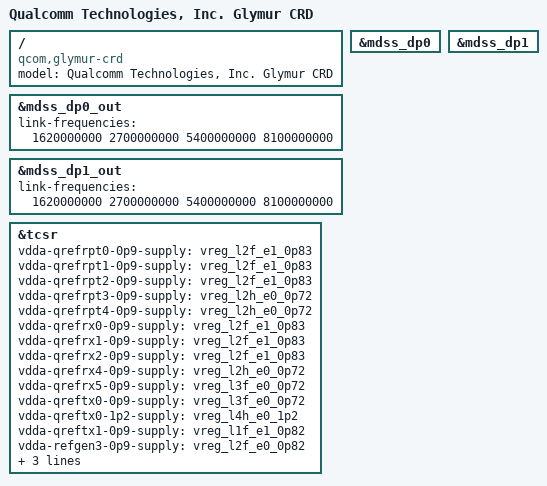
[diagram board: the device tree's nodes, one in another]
// SPDX-License-Identifier: BSD-3-Clause
/*
 * Copyright (c) Qualcomm Technologies, Inc. and/or its subsidiaries.
 */

/dts-v1/;

#include "glymur.dtsi"
#include "glymur-crd.dtsi"

/ {
	model = "Qualcomm Technologies, Inc. Glymur CRD";
	compatible = "qcom,glymur-crd", "qcom,glymur";
};

&mdss_dp0 {
	status = "okay";
};

&mdss_dp0_out {
	link-frequencies = /bits/ 64 <1620000000 2700000000 5400000000 8100000000>;
};

&mdss_dp1 {
	status = "okay";
};

&mdss_dp1_out {
	link-frequencies = /bits/ 64 <1620000000 2700000000 5400000000 8100000000>;
};

&tcsr {
	vdda-qrefrpt0-0p9-supply = <&vreg_l2f_e1_0p83>;
	vdda-qrefrpt1-0p9-supply = <&vreg_l2f_e1_0p83>;
	vdda-qrefrpt2-0p9-supply = <&vreg_l2f_e1_0p83>;
	vdda-qrefrpt3-0p9-supply = <&vreg_l2h_e0_0p72>;
	vdda-qrefrpt4-0p9-supply = <&vreg_l2h_e0_0p72>;
	vdda-qrefrx0-0p9-supply = <&vreg_l2f_e1_0p83>;
	vdda-qrefrx1-0p9-supply = <&vreg_l2f_e1_0p83>;
	vdda-qrefrx2-0p9-supply = <&vreg_l2f_e1_0p83>;
	vdda-qrefrx4-0p9-supply = <&vreg_l2h_e0_0p72>;
	vdda-qrefrx5-0p9-supply = <&vreg_l3f_e0_0p72>;
	vdda-qreftx0-0p9-supply = <&vreg_l3f_e0_0p72>;
	vdda-qreftx0-1p2-supply = <&vreg_l4h_e0_1p2>;
	vdda-qreftx1-0p9-supply = <&vreg_l1f_e1_0p82>;
	vdda-refgen3-0p9-supply = <&vreg_l2f_e0_0p82>;
	vdda-refgen3-1p2-supply = <&vreg_l4h_e0_1p2>;
	vdda-refgen4-0p9-supply = <&vreg_l1f_e1_0p82>;
	vdda-refgen4-1p2-supply = <&vreg_l4f_e1_1p08>;
};
